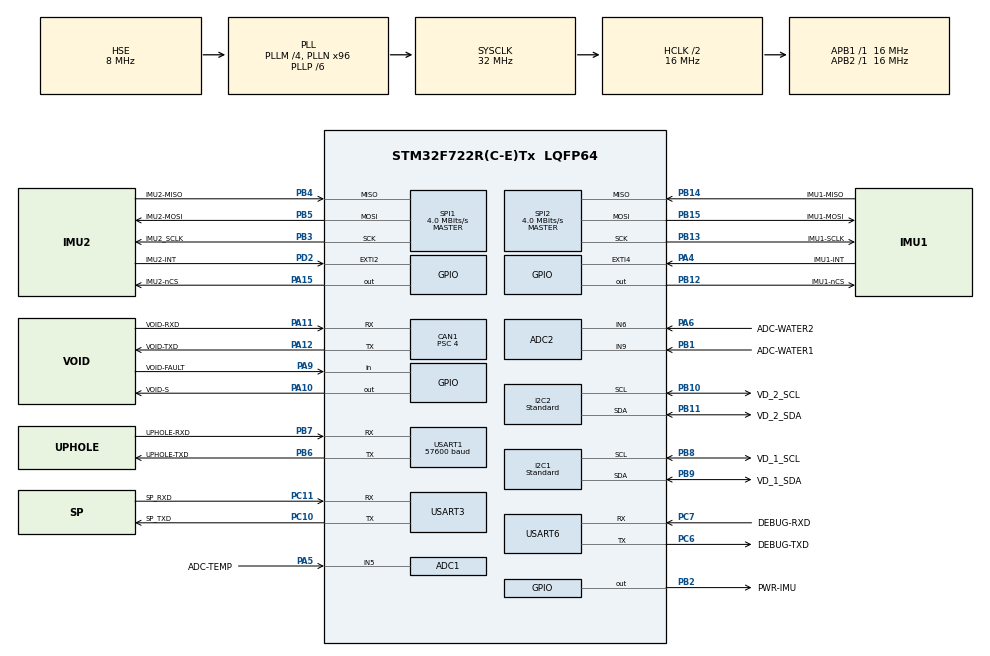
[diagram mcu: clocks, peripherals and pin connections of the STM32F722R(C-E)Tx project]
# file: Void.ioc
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ADC1.Channel-0\#ChannelRegularConversion=ADC_CHANNEL_5
ADC1.DMAContinuousRequests=ENABLE
ADC1.EnableAnalogWatchDog=false
ADC1.ExternalTrigConv=ADC_EXTERNALTRIGCONV_T2_TRGO
ADC1.NbrOfConversionFlag=1
ADC1.Rank-0\#ChannelRegularConversion=1
ADC1.SamplingTime-0\#ChannelRegularConversion=ADC_SAMPLETIME_3CYCLES
ADC1.ScanConvMode=ADC_SCAN_DISABLE
ADC1.master=1
ADC2.Channel-0\#ChannelRegularConversion=ADC_CHANNEL_9
ADC2.Channel-1\#ChannelRegularConversion=ADC_CHANNEL_6
ADC2.DMAContinuousRequests=ENABLE
ADC2.EnableAnalogWatchDog=false
ADC2.ExternalTrigConv=ADC_EXTERNALTRIGCONV_T4_TRGO
ADC2.NbrOfConversion=2
ADC2.NbrOfConversionFlag=1
ADC2.Rank-0\#ChannelRegularConversion=1
ADC2.Rank-1\#ChannelRegularConversion=2
ADC2.SamplingTime-0\#ChannelRegularConversion=ADC_SAMPLETIME_480CYCLES
ADC2.SamplingTime-1\#ChannelRegularConversion=ADC_SAMPLETIME_480CYCLES
CAN1.BS1=CAN_BS1_5TQ
CAN1.BS2=CAN_BS2_2TQ
CAN1.CalculateBaudRate=500000
CAN1.CalculateTimeBit=2000
CAN1.CalculateTimeQuantum=250.0
CAN1.Prescaler=4
Dma.ADC1.1.Direction=DMA_PERIPH_TO_MEMORY
Dma.ADC1.1.FIFOMode=DMA_FIFOMODE_DISABLE
Dma.ADC1.1.Instance=DMA2_Stream4
Dma.ADC1.1.MemDataAlignment=DMA_MDATAALIGN_HALFWORD
Dma.ADC1.1.MemInc=DMA_MINC_ENABLE
Dma.ADC1.1.Mode=DMA_CIRCULAR
Dma.ADC1.1.PeriphDataAlignment=DMA_PDATAALIGN_HALFWORD
Dma.ADC1.1.PeriphInc=DMA_PINC_DISABLE
Dma.ADC1.1.Priority=DMA_PRIORITY_LOW
Dma.ADC2.0.Direction=DMA_PERIPH_TO_MEMORY
Dma.ADC2.0.FIFOMode=DMA_FIFOMODE_DISABLE
Dma.ADC2.0.Instance=DMA2_Stream2
Dma.ADC2.0.MemDataAlignment=DMA_MDATAALIGN_HALFWORD
Dma.ADC2.0.MemInc=DMA_MINC_ENABLE
Dma.ADC2.0.Mode=DMA_CIRCULAR
Dma.ADC2.0.PeriphDataAlignment=DMA_PDATAALIGN_HALFWORD
Dma.ADC2.0.PeriphInc=DMA_PINC_DISABLE
Dma.ADC2.0.Priority=DMA_PRIORITY_LOW
Dma.I2C1_RX.9.Direction=DMA_PERIPH_TO_MEMORY
Dma.I2C1_RX.9.FIFOMode=DMA_FIFOMODE_DISABLE
Dma.I2C1_RX.9.Instance=DMA1_Stream0
Dma.I2C1_RX.9.MemDataAlignment=DMA_MDATAALIGN_BYTE
Dma.I2C1_RX.9.MemInc=DMA_MINC_ENABLE
Dma.I2C1_RX.9.Mode=DMA_NORMAL
Dma.I2C1_RX.9.PeriphDataAlignment=DMA_PDATAALIGN_BYTE
Dma.I2C1_RX.9.PeriphInc=DMA_PINC_DISABLE
Dma.I2C1_RX.9.Priority=DMA_PRIORITY_LOW
Dma.I2C1_TX.10.Direction=DMA_MEMORY_TO_PERIPH
Dma.I2C1_TX.10.FIFOMode=DMA_FIFOMODE_DISABLE
Dma.I2C1_TX.10.Instance=DMA1_Stream6
Dma.I2C1_TX.10.MemDataAlignment=DMA_MDATAALIGN_BYTE
Dma.I2C1_TX.10.MemInc=DMA_MINC_ENABLE
Dma.I2C1_TX.10.Mode=DMA_NORMAL
Dma.I2C1_TX.10.PeriphDataAlignment=DMA_PDATAALIGN_BYTE
Dma.I2C1_TX.10.PeriphInc=DMA_PINC_DISABLE
Dma.I2C1_TX.10.Priority=DMA_PRIORITY_LOW
Dma.I2C2_RX.11.Direction=DMA_PERIPH_TO_MEMORY
Dma.I2C2_RX.11.FIFOMode=DMA_FIFOMODE_DISABLE
Dma.I2C2_RX.11.Instance=DMA1_Stream2
Dma.I2C2_RX.11.MemDataAlignment=DMA_MDATAALIGN_BYTE
Dma.I2C2_RX.11.MemInc=DMA_MINC_ENABLE
Dma.I2C2_RX.11.Mode=DMA_NORMAL
Dma.I2C2_RX.11.PeriphDataAlignment=DMA_PDATAALIGN_BYTE
Dma.I2C2_RX.11.PeriphInc=DMA_PINC_DISABLE
Dma.I2C2_RX.11.Priority=DMA_PRIORITY_MEDIUM
Dma.I2C2_TX.12.Direction=DMA_MEMORY_TO_PERIPH
Dma.I2C2_TX.12.FIFOMode=DMA_FIFOMODE_DISABLE
Dma.I2C2_TX.12.Instance=DMA1_Stream7
Dma.I2C2_TX.12.MemDataAlignment=DMA_MDATAALIGN_BYTE
Dma.I2C2_TX.12.MemInc=DMA_MINC_ENABLE
Dma.I2C2_TX.12.Mode=DMA_NORMAL
Dma.I2C2_TX.12.PeriphDataAlignment=DMA_PDATAALIGN_BYTE
Dma.I2C2_TX.12.PeriphInc=DMA_PINC_DISABLE
Dma.I2C2_TX.12.Priority=DMA_PRIORITY_MEDIUM
Dma.Request0=ADC2
Dma.Request1=ADC1
Dma.Request10=I2C1_TX
Dma.Request11=I2C2_RX
Dma.Request12=I2C2_TX
Dma.Request2=USART1_RX
Dma.Request3=SPI1_TX
Dma.Request4=SPI1_RX
Dma.Request5=SPI2_TX
Dma.Request6=SPI2_RX
Dma.Request7=USART6_RX
Dma.Request8=USART3_RX
Dma.Request9=I2C1_RX
Dma.SPI1_RX.4.Direction=DMA_PERIPH_TO_MEMORY
Dma.SPI1_RX.4.FIFOMode=DMA_FIFOMODE_DISABLE
Dma.SPI1_RX.4.Instance=DMA2_Stream0
Dma.SPI1_RX.4.MemDataAlignment=DMA_MDATAALIGN_BYTE
Dma.SPI1_RX.4.MemInc=DMA_MINC_ENABLE
Dma.SPI1_RX.4.Mode=DMA_NORMAL
Dma.SPI1_RX.4.PeriphDataAlignment=DMA_PDATAALIGN_BYTE
Dma.SPI1_RX.4.PeriphInc=DMA_PINC_DISABLE
Dma.SPI1_RX.4.Priority=DMA_PRIORITY_LOW
Dma.SPI1_TX.3.Direction=DMA_MEMORY_TO_PERIPH
Dma.SPI1_TX.3.FIFOMode=DMA_FIFOMODE_DISABLE
Dma.SPI1_TX.3.Instance=DMA2_Stream3
Dma.SPI1_TX.3.MemDataAlignment=DMA_MDATAALIGN_BYTE
Dma.SPI1_TX.3.MemInc=DMA_MINC_ENABLE
Dma.SPI1_TX.3.Mode=DMA_NORMAL
Dma.SPI1_TX.3.PeriphDataAlignment=DMA_PDATAALIGN_BYTE
Dma.SPI1_TX.3.PeriphInc=DMA_PINC_DISABLE
Dma.SPI1_TX.3.Priority=DMA_PRIORITY_LOW
Dma.SPI2_RX.6.Direction=DMA_PERIPH_TO_MEMORY
Dma.SPI2_RX.6.FIFOMode=DMA_FIFOMODE_DISABLE
Dma.SPI2_RX.6.Instance=DMA1_Stream3
Dma.SPI2_RX.6.MemDataAlignment=DMA_MDATAALIGN_BYTE
Dma.SPI2_RX.6.MemInc=DMA_MINC_ENABLE
Dma.SPI2_RX.6.Mode=DMA_NORMAL
Dma.SPI2_RX.6.PeriphDataAlignment=DMA_PDATAALIGN_BYTE
Dma.SPI2_RX.6.PeriphInc=DMA_PINC_DISABLE
Dma.SPI2_RX.6.Priority=DMA_PRIORITY_LOW
Dma.SPI2_TX.5.Direction=DMA_MEMORY_TO_PERIPH
Dma.SPI2_TX.5.FIFOMode=DMA_FIFOMODE_DISABLE
Dma.SPI2_TX.5.Instance=DMA1_Stream4
Dma.SPI2_TX.5.MemDataAlignment=DMA_MDATAALIGN_BYTE
Dma.SPI2_TX.5.MemInc=DMA_MINC_ENABLE
Dma.SPI2_TX.5.Mode=DMA_NORMAL
Dma.SPI2_TX.5.PeriphDataAlignment=DMA_PDATAALIGN_BYTE
Dma.SPI2_TX.5.PeriphInc=DMA_PINC_DISABLE
Dma.SPI2_TX.5.Priority=DMA_PRIORITY_LOW
Dma.USART1_RX.2.Direction=DMA_PERIPH_TO_MEMORY
Dma.USART1_RX.2.FIFOMode=DMA_FIFOMODE_DISABLE
Dma.USART1_RX.2.Instance=DMA2_Stream5
Dma.USART1_RX.2.MemDataAlignment=DMA_MDATAALIGN_BYTE
Dma.USART1_RX.2.MemInc=DMA_MINC_ENABLE
Dma.USART1_RX.2.Mode=DMA_CIRCULAR
Dma.USART1_RX.2.PeriphDataAlignment=DMA_PDATAALIGN_BYTE
Dma.USART1_RX.2.PeriphInc=DMA_PINC_DISABLE
Dma.USART1_RX.2.Priority=DMA_PRIORITY_LOW
Dma.USART3_RX.8.Direction=DMA_PERIPH_TO_MEMORY
Dma.USART3_RX.8.FIFOMode=DMA_FIFOMODE_DISABLE
Dma.USART3_RX.8.Instance=DMA1_Stream1
Dma.USART3_RX.8.MemDataAlignment=DMA_MDATAALIGN_BYTE
Dma.USART3_RX.8.MemInc=DMA_MINC_ENABLE
Dma.USART3_RX.8.Mode=DMA_CIRCULAR
Dma.USART3_RX.8.PeriphDataAlignment=DMA_PDATAALIGN_BYTE
Dma.USART3_RX.8.PeriphInc=DMA_PINC_DISABLE
Dma.USART3_RX.8.Priority=DMA_PRIORITY_LOW
Dma.USART6_RX.7.Direction=DMA_PERIPH_TO_MEMORY
Dma.USART6_RX.7.FIFOMode=DMA_FIFOMODE_DISABLE
Dma.USART6_RX.7.Instance=DMA2_Stream1
Dma.USART6_RX.7.MemDataAlignment=DMA_MDATAALIGN_BYTE
Dma.USART6_RX.7.MemInc=DMA_MINC_ENABLE
Dma.USART6_RX.7.Mode=DMA_CIRCULAR
Dma.USART6_RX.7.PeriphDataAlignment=DMA_PDATAALIGN_BYTE
Dma.USART6_RX.7.PeriphInc=DMA_PINC_DISABLE
Dma.USART6_RX.7.Priority=DMA_PRIORITY_LOW
I2C1.Analog_Filter=I2C_ANALOGFILTER_ENABLE
I2C1.I2C_Fall_Time=225
I2C1.I2C_Rise_Time=225
I2C1.I2C_Speed_Mode=I2C_Standard
I2C1.Timing=0x2020141B
I2C2.I2C_Fall_Time=100
I2C2.I2C_Rise_Time=150
I2C2.I2C_Speed_Mode=I2C_Standard
I2C2.Speed=100
I2C2.Timing=0x2020151B
Mcu.Family=STM32F7
Mcu.Name=STM32F722R(C-E)Tx
Mcu.Package=LQFP64
NVIC.CAN1_RX0_IRQn=true\:0\:0\:false\:false\:true\:true\:true\:true
NVIC.CAN1_RX1_IRQn=true\:0\:0\:false\:false\:true\:true\:true\:true
NVIC.DMA1_Stream0_IRQn=true\:0\:0\:false\:false\:true\:false\:true\:true
NVIC.DMA1_Stream1_IRQn=true\:0\:0\:false\:false\:true\:false\:true\:true
NVIC.DMA1_Stream2_IRQn=true\:0\:0\:false\:false\:true\:false\:true\:true
NVIC.DMA1_Stream3_IRQn=true\:0\:0\:false\:false\:true\:false\:true\:true
NVIC.DMA1_Stream4_IRQn=true\:0\:0\:false\:false\:true\:false\:true\:true
NVIC.DMA1_Stream6_IRQn=true\:0\:0\:false\:false\:true\:false\:true\:true
NVIC.DMA1_Stream7_IRQn=true\:0\:0\:false\:false\:true\:false\:true\:true
NVIC.DMA2_Stream0_IRQn=true\:0\:0\:false\:false\:true\:false\:true\:true
NVIC.DMA2_Stream1_IRQn=true\:0\:0\:false\:false\:true\:false\:true\:true
NVIC.DMA2_Stream2_IRQn=true\:0\:0\:false\:false\:true\:false\:true\:true
NVIC.DMA2_Stream3_IRQn=true\:0\:0\:false\:false\:true\:false\:true\:true
NVIC.DMA2_Stream4_IRQn=true\:0\:0\:false\:false\:true\:false\:true\:true
NVIC.DMA2_Stream5_IRQn=true\:0\:0\:false\:false\:true\:false\:true\:true
NVIC.EXTI2_IRQn=true\:0\:0\:false\:false\:true\:true\:true\:true
NVIC.EXTI4_IRQn=true\:0\:0\:false\:false\:true\:true\:true\:true
NVIC.I2C1_ER_IRQn=true\:0\:0\:false\:false\:true\:true\:true\:true
NVIC.I2C1_EV_IRQn=true\:0\:0\:false\:false\:true\:true\:true\:true
NVIC.I2C2_ER_IRQn=true\:0\:0\:false\:false\:true\:true\:true\:true
NVIC.I2C2_EV_IRQn=true\:0\:0\:false\:false\:true\:true\:true\:true
NVIC.PriorityGroup=NVIC_PRIORITYGROUP_4
NVIC.TIM7_IRQn=true\:0\:0\:false\:false\:true\:true\:true\:true
NVIC.USART1_IRQn=true\:0\:0\:false\:false\:true\:true\:true\:true
NVIC.USART3_IRQn=true\:0\:0\:false\:false\:true\:true\:true\:true
NVIC.USART6_IRQn=true\:0\:0\:false\:false\:true\:true\:true\:true
PA10.GPIO_Label=VOID-S
PA10.Signal=GPIO_Output
PA11.GPIO_Label=VOID-RXD
PA11.Mode=CAN_Activate
PA11.Signal=CAN1_RX
PA12.GPIO_Label=VOID-TXD
PA12.Mode=CAN_Activate
PA12.Signal=CAN1_TX
PA13.Mode=Serial_Wire
PA13.Signal=SYS_JTMS-SWDIO
PA14.Mode=Serial_Wire
PA14.Signal=SYS_JTCK-SWCLK
PA15.GPIO_Label=IMU2-nCS
PA15.PinState=GPIO_PIN_SET
PA15.Signal=GPIO_Output
PA4.GPIO_Label=IMU1-INT
PA4.Signal=GPXTI4
PA5.GPIO_Label=ADC-TEMP
PA5.Signal=SharedAnalog_PA5
PA6.GPIO_Label=ADC-WATER2
PA6.Signal=ADCx_IN6
PA9.GPIO_Label=VOID-FAULT
PA9.Signal=GPIO_Input
PB1.GPIO_Label=ADC-WATER1
PB1.Signal=ADCx_IN9
PB10.GPIO_Label=VD_2_SCL
PB10.Mode=I2C
PB10.Signal=I2C2_SCL
PB11.GPIO_Label=VD_2_SDA
PB11.Mode=I2C
PB11.Signal=I2C2_SDA
PB12.GPIO_Label=IMU1-nCS
PB12.PinState=GPIO_PIN_SET
PB12.Signal=GPIO_Output
PB13.GPIO_Label=IMU1-SCLK
PB13.Mode=Full_Duplex_Master
PB13.Signal=SPI2_SCK
PB14.GPIO_Label=IMU1-MISO
PB14.Mode=Full_Duplex_Master
PB14.Signal=SPI2_MISO
PB15.GPIO_Label=IMU1-MOSI
PB15.Mode=Full_Duplex_Master
PB15.Signal=SPI2_MOSI
PB2.GPIO_Label=PWR-IMU
PB2.Signal=GPIO_Output
PB3.GPIO_Label=IMU2_SCLK
PB3.Mode=Full_Duplex_Master
PB3.Signal=SPI1_SCK
PB4.GPIO_Label=IMU2-MISO
PB4.Mode=Full_Duplex_Master
PB4.Signal=SPI1_MISO
PB5.GPIO_Label=IMU2-MOSI
PB5.Mode=Full_Duplex_Master
PB5.Signal=SPI1_MOSI
PB6.GPIO_Label=UPHOLE-TXD
PB6.GPIO_PuPd=GPIO_PULLUP
PB6.Mode=Asynchronous
PB6.Signal=USART1_TX
PB7.GPIO_Label=UPHOLE-RXD
PB7.GPIO_PuPd=GPIO_PULLUP
PB7.Mode=Asynchronous
PB7.Signal=USART1_RX
PB8.GPIO_Label=VD_1_SCL
PB8.Mode=I2C
PB8.Signal=I2C1_SCL
PB9.GPIO_Label=VD_1_SDA
PB9.Mode=I2C
PB9.Signal=I2C1_SDA
PC10.GPIO_Label=SP_TXD
PC10.Mode=Asynchronous
PC10.Signal=USART3_TX
PC11.GPIO_Label=SP_RXD
PC11.Mode=Asynchronous
PC11.Signal=USART3_RX
PC14-OSC32_IN.Mode=LSE-External-Oscillator
PC14-OSC32_IN.Signal=RCC_OSC32_IN
PC15-OSC32_OUT.Mode=LSE-External-Oscillator
PC15-OSC32_OUT.Signal=RCC_OSC32_OUT
PC6.GPIO_Label=DEBUG-TXD
PC6.GPIO_PuPd=GPIO_PULLUP
PC6.Mode=Asynchronous
PC6.Signal=USART6_TX
PC7.GPIO_Label=DEBUG-RXD
PC7.GPIO_PuPd=GPIO_PULLUP
PC7.Mode=Asynchronous
PC7.Signal=USART6_RX
PD2.GPIO_Label=IMU2-INT
PD2.Signal=GPXTI2
PH0-OSC_IN.Mode=HSE-External-Oscillator
PH0-OSC_IN.Signal=RCC_OSC_IN
PH1-OSC_OUT.Mode=HSE-External-Oscillator
PH1-OSC_OUT.Signal=RCC_OSC_OUT
ProjectManager.HeapSize=0x400
ProjectManager.StackSize=0x400
ProjectManager.TargetToolchain=MDK-ARM V5
RCC.AHBCLKDivider=RCC_SYSCLK_DIV2
RCC.AHBFreq_Value=16000000
RCC.APB1Freq_Value=16000000
RCC.APB1TimFreq_Value=16000000
RCC.APB2Freq_Value=16000000
RCC.APB2TimFreq_Value=16000000
RCC.CortexFreq_Value=16000000
RCC.HCLKFreq_Value=16000000
RCC.HSE_VALUE=8000000
RCC.HSI_VALUE=16000000
RCC.PLLM=4
RCC.PLLN=96
RCC.PLLP=RCC_PLLP_DIV6
RCC.PLLSourceVirtual=RCC_PLLSOURCE_HSE
RCC.SYSCLKFreq_VALUE=32000000
RCC.SYSCLKSource=RCC_SYSCLKSOURCE_PLLCLK
RCC.USBFreq_Value=96000000
RCC.VCOOutputFreq_Value=192000000
SH.ADCx_IN6.0=ADC2_IN6,IN6
SH.ADCx_IN9.0=ADC2_IN9,IN9
SH.SharedAnalog_PA5.0=GPIO_Analog
SH.SharedAnalog_PA5.1=ADC1_IN5,IN5
SPI1.BaudRatePrescaler=SPI_BAUDRATEPRESCALER_4
SPI1.CLKPhase=SPI_PHASE_2EDGE
SPI1.CLKPolarity=SPI_POLARITY_HIGH
SPI1.CalculateBaudRate=4.0 MBits/s
SPI1.DataSize=SPI_DATASIZE_8BIT
SPI1.Direction=SPI_DIRECTION_2LINES
SPI1.Mode=SPI_MODE_MASTER
SPI1.VirtualType=VM_MASTER
SPI2.BaudRatePrescaler=SPI_BAUDRATEPRESCALER_4
SPI2.CLKPhase=SPI_PHASE_2EDGE
SPI2.CLKPolarity=SPI_POLARITY_HIGH
SPI2.CalculateBaudRate=4.0 MBits/s
SPI2.DataSize=SPI_DATASIZE_8BIT
SPI2.Direction=SPI_DIRECTION_2LINES
SPI2.Mode=SPI_MODE_MASTER
SPI2.VirtualType=VM_MASTER
TIM2.Period=16000000 / 400 - 1
TIM2.Prescaler=1 - 1
TIM2.TIM_MasterOutputTrigger=TIM_TRGO_OC1
TIM4.Period=16000000 / 400 - 1
TIM4.Prescaler=1 - 1
TIM4.TIM_MasterOutputTrigger=TIM_TRGO_OC1
TIM5.Period=16000000 / 400 - 1
TIM5.Prescaler=1 - 1
TIM5.TIM_MasterOutputTrigger=TIM_TRGO_OC1
TIM7.Period=16000-1
TIM7.Prescaler=1-1
USART1.BaudRate=57600
USART1.SwapParam=ADVFEATURE_SWAP_ENABLE
USART1.VirtualMode-Asynchronous=VM_ASYNC
USART3.VirtualMode-Asynchronous=VM_ASYNC
USART6.VirtualMode=VM_ASYNC
VP_TIM2_VS_ClockSourceINT.Mode=Internal
VP_TIM4_VS_ClockSourceINT.Mode=Internal
VP_TIM5_VS_ClockSourceINT.Mode=Internal
VP_TIM7_VS_ClockSourceINT.Mode=Enable_Timer
board=custom

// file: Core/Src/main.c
/* USER CODE BEGIN Header */
/**
 ******************************************************************************
 * @file           : main.c
 * @brief          : Main program body
 ******************************************************************************
 * @attention
 *
 * <h2><center>&copy; Copyright (c) 2020 STMicroelectronics.
 * All rights reserved.</center></h2>
 *
 * This software component is licensed by ST under BSD 3-Clause license,
 * the "License"; You may not use this file except in compliance with the
 * License. You may obtain a copy of the License at:
 *                        opensource.org/licenses/BSD-3-Clause
 *
 ******************************************************************************
 */
/* USER CODE END Header */
#include "main.h"
#include "adc.h"
#include "can.h"
#include "dma.h"
#include "i2c.h"
#include "spi.h"
#include "tim.h"
#include "usart.h"
#include "gpio.h"

/* USER CODE BEGIN Includes */
#include "vmt_device.h"

/* USER CODE END Includes */

void SystemClock_Config(void);

int main(void)
{

    /* MCU Configuration--------------------------------------------------------*/

    /* Reset of all peripherals, Initializes the Flash interface and the Systick. */
    HAL_Init();

    /* Configure the system clock */
    SystemClock_Config();

    /* Initialize all configured peripherals */
    MX_GPIO_Init();
    MX_DMA_Init();
    MX_ADC1_Init();
    MX_ADC2_Init();
    MX_SPI1_Init();
    MX_SPI2_Init();
    MX_USART1_UART_Init();
    MX_TIM2_Init();
    MX_TIM4_Init();
    MX_TIM5_Init();
    MX_TIM7_Init();
    MX_USART6_UART_Init();
    MX_I2C1_Init();
    MX_I2C2_Init();
    MX_CAN1_Init();
    MX_USART3_UART_Init();

    /* Infinite loop */
    while (1)
    {

        /* USER CODE BEGIN 3 */
        device_process();
    }
    /* USER CODE END 3 */
}

void SystemClock_Config(void)
{
    RCC_OscInitTypeDef RCC_OscInitStruct = { 0 };
    RCC_ClkInitTypeDef RCC_ClkInitStruct = { 0 };

    /** Configure LSE Drive Capability
     */
    HAL_PWR_EnableBkUpAccess();

    /** Configure the main internal regulator output voltage
     */
    __HAL_RCC_PWR_CLK_ENABLE();
    __HAL_PWR_VOLTAGESCALING_CONFIG(PWR_REGULATOR_VOLTAGE_SCALE3);

    /** Initializes the RCC Oscillators according to the specified parameters
     * in the RCC_OscInitTypeDef structure.
     */
    RCC_OscInitStruct.OscillatorType = RCC_OSCILLATORTYPE_HSE;
    RCC_OscInitStruct.HSEState       = RCC_HSE_ON;
    RCC_OscInitStruct.PLL.PLLState   = RCC_PLL_ON;
    RCC_OscInitStruct.PLL.PLLSource  = RCC_PLLSOURCE_HSE;
    RCC_OscInitStruct.PLL.PLLM       = 4;
    RCC_OscInitStruct.PLL.PLLN       = 96;
    RCC_OscInitStruct.PLL.PLLP       = RCC_PLLP_DIV6;
    RCC_OscInitStruct.PLL.PLLQ       = 2;
    if (HAL_RCC_OscConfig(&RCC_OscInitStruct) != HAL_OK)
    {
        Error_Handler();
    }

    /** Initializes the CPU, AHB and APB buses clocks
     */
    RCC_ClkInitStruct.ClockType      = RCC_CLOCKTYPE_HCLK | RCC_CLOCKTYPE_SYSCLK | RCC_CLOCKTYPE_PCLK1 | RCC_CLOCKTYPE_PCLK2;
    RCC_ClkInitStruct.SYSCLKSource   = RCC_SYSCLKSOURCE_PLLCLK;
    RCC_ClkInitStruct.AHBCLKDivider  = RCC_SYSCLK_DIV2;
    RCC_ClkInitStruct.APB1CLKDivider = RCC_HCLK_DIV1;
    RCC_ClkInitStruct.APB2CLKDivider = RCC_HCLK_DIV1;

    if (HAL_RCC_ClockConfig(&RCC_ClkInitStruct, FLASH_LATENCY_0) != HAL_OK)
    {
        Error_Handler();
    }
}

void Error_Handler(void)
{
}
